AUTOSAR XML (schema 4-2-2)
package /ComponentTypes
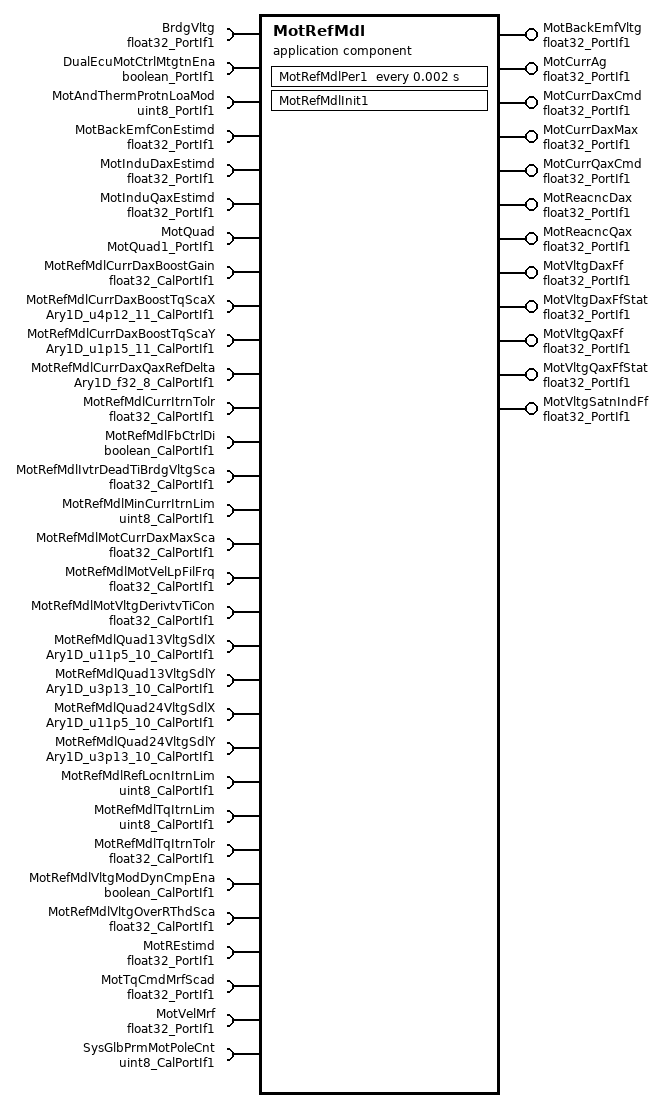
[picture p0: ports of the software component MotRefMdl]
  application sw component type MotRefMdl
    12 x provide port, all with nonqueued-sender-com-spec{data-element=Val, init-value=0}, provided-interface=float32_PortIf1:
      MotBackEmfVltg
      MotCurrAg
      MotCurrDaxCmd
      MotCurrDaxMax
      MotCurrQaxCmd
      MotReacncDax
      MotReacncQax
      MotVltgDaxFf
      MotVltgDaxFfStat
      MotVltgQaxFf
      MotVltgQaxFfStat
      MotVltgSatnIndFf
    31 x require port:
      BrdgVltg: nonqueued-receiver-com-spec{data-element=Val, filter=data-filter-type=ALWAYS, init-value=6}, required-interface=float32_PortIf1
      DualEcuMotCtrlMtgtnEna: nonqueued-receiver-com-spec{data-element=Logl, filter=data-filter-type=ALWAYS, init-value=0}, required-interface=boolean_PortIf1
      MotAndThermProtnLoaMod: nonqueued-receiver-com-spec{data-element=Val, filter=data-filter-type=ALWAYS, init-value=0}, required-interface=uint8_PortIf1
      MotBackEmfConEstimd: nonqueued-receiver-com-spec{data-element=Val, filter=data-filter-type=ALWAYS, init-value=0.025}, required-interface=float32_PortIf1
      MotInduDaxEstimd: nonqueued-receiver-com-spec{data-element=Val, filter=data-filter-type=ALWAYS, init-value=0.00011889}, required-interface=float32_PortIf1
      MotInduQaxEstimd: nonqueued-receiver-com-spec{data-element=Val, filter=data-filter-type=ALWAYS, init-value=0.00011889}, required-interface=float32_PortIf1
      MotQuad: nonqueued-receiver-com-spec{data-element=Val, filter=data-filter-type=ALWAYS, init-value=1}, required-interface=MotQuad1_PortIf1
      MotRefMdlCurrDaxBoostGain: parameter-require-com-spec{init-value=0, parameter=Val}, required-interface=float32_CalPortIf1
      MotRefMdlCurrDaxBoostTqScaX: parameter-require-com-spec{init-value=[0, 6144, 7168, 8192, 9216, 10240, 12288, 14336, 16384, 18432, 20480], parameter=Ary1D}, required-interface=Ary1D_u4p12_11_CalPortIf1
      MotRefMdlCurrDaxBoostTqScaY: parameter-require-com-spec{init-value=[0, 16384, 19661, 22938, 23757, 25395, 27034, 27853, 29491, 31130, 32768], parameter=Ary1D}, required-interface=Ary1D_u1p15_11_CalPortIf1
      MotRefMdlCurrDaxQaxRefDelta: parameter-require-com-spec{init-value=[-3.1415927, -2.3561945, -1.5707964, -0.7853982, 0, 0.7853982, 1.5707964, 2.3561945], parameter=Ary1D}, required-interface=Ary1D_f32_8_CalPortIf1
      MotRefMdlCurrItrnTolr: parameter-require-com-spec{init-value=0.1, parameter=Val}, required-interface=float32_CalPortIf1
      MotRefMdlFbCtrlDi: parameter-require-com-spec{init-value=0, parameter=Logl}, required-interface=boolean_CalPortIf1
      MotRefMdlIvtrDeadTiBrdgVltgSca: parameter-require-com-spec{init-value=1, parameter=Val}, required-interface=float32_CalPortIf1
      MotRefMdlMinCurrItrnLim: parameter-require-com-spec{init-value=3, parameter=Val}, required-interface=uint8_CalPortIf1
      MotRefMdlMotCurrDaxMaxSca: parameter-require-com-spec{init-value=1, parameter=Val}, required-interface=float32_CalPortIf1
      MotRefMdlMotVelLpFilFrq: parameter-require-com-spec{init-value=125, parameter=Val}, required-interface=float32_CalPortIf1
      MotRefMdlMotVltgDerivtvTiCon: parameter-require-com-spec{init-value=0.0026526, parameter=Val}, required-interface=float32_CalPortIf1
      MotRefMdlQuad13VltgSdlX: parameter-require-com-spec{init-value=[0, 3200, 6400, 9600, 16000, 19200, 22400, 25600, 28800, 35200], parameter=Ary1D}, required-interface=Ary1D_u11p5_10_CalPortIf1
      MotRefMdlQuad13VltgSdlY: parameter-require-com-spec{init-value=10 x 0, parameter=Ary1D}, required-interface=Ary1D_u3p13_10_CalPortIf1
      MotRefMdlQuad24VltgSdlX: parameter-require-com-spec{init-value=[0, 3200, 6400, 9600, 16000, 19200, 22400, 25600, 28800, 35200], parameter=Ary1D}, required-interface=Ary1D_u11p5_10_CalPortIf1
      MotRefMdlQuad24VltgSdlY: parameter-require-com-spec{init-value=10 x 0, parameter=Ary1D}, required-interface=Ary1D_u3p13_10_CalPortIf1
      MotRefMdlRefLocnItrnLim: parameter-require-com-spec{init-value=10, parameter=Val}, required-interface=uint8_CalPortIf1
      MotRefMdlTqItrnLim: parameter-require-com-spec{init-value=3, parameter=Val}, required-interface=uint8_CalPortIf1
      MotRefMdlTqItrnTolr: parameter-require-com-spec{init-value=0.015, parameter=Val}, required-interface=float32_CalPortIf1
      MotRefMdlVltgModDynCmpEna: parameter-require-com-spec{init-value=0, parameter=Logl}, required-interface=boolean_CalPortIf1
      MotRefMdlVltgOverRThdSca: parameter-require-com-spec{init-value=0.25, parameter=Val}, required-interface=float32_CalPortIf1
      MotREstimd: nonqueued-receiver-com-spec{data-element=Val, filter=data-filter-type=ALWAYS, init-value=0.0139083}, required-interface=float32_PortIf1
      MotTqCmdMrfScad: nonqueued-receiver-com-spec{data-element=Val, filter=data-filter-type=ALWAYS, init-value=0}, required-interface=float32_PortIf1
      MotVelMrf: nonqueued-receiver-com-spec{data-element=Val, filter=data-filter-type=ALWAYS, init-value=0}, required-interface=float32_PortIf1
      SysGlbPrmMotPoleCnt: parameter-require-com-spec{init-value=8, parameter=Val}, required-interface=uint8_CalPortIf1
    behavior MotRefMdl_InternalBehavior: data-type-mapping=Nexteer
      ar-typed-per-instance-memorys:
        28 x data, all with sw-calibration-access=READ-ONLY:
          CosDelta: type=Ary1D_f32_8
          dMotRefMdlCurrDaxAtPeakTq: type=float32
          dMotRefMdlCurrDaxMin: type=float32
          dMotRefMdlCurrQaxMin: type=float32
          dMotRefMdlCurrSqdMin: type=float32
          dMotRefMdlInterCalcnCurrDaxMax: type=float32
          dMotRefMdlMinCurrNrItrn: type=uint8
          dMotRefMdlMotCurrDaxBoost: type=float32
          dMotRefMdlMotTqCmdLimd: type=float32
          dMotRefMdlMotVelFildFf: type=float32
          dMotRefMdlMotVltgDaxFfDyn: type=float32
          dMotRefMdlMotVltgDaxFfDynTerm: type=float32
          dMotRefMdlMotVltgDaxFfStat: type=float32
          dMotRefMdlMotVltgQaxFfDyn: type=float32
          dMotRefMdlMotVltgQaxFfDynTerm: type=float32
          dMotRefMdlMotVltgQaxFfStat: type=float32
          dMotRefMdlPeakTq: type=float32
          dMotRefMdlPeakTqNrItrn: type=uint8
          dMotRefMdlPhaAdvAtPeakTq: type=float32
          dMotRefMdlReacncDaxOverR: type=float32
          dMotRefMdlReacncQaxOverR: type=float32
          dMotRefMdlRelncTqCoeff: type=float32
          MotCurrDaxCmdPrev: type=float32
          MotCurrQaxCmdPrev: type=float32
          MotVelLpFil: type=FilLpRec1
          SinDelta: type=Ary1D_f32_8
          VltgDaxFfTermPrev: type=float32
          VltgQaxFfTermPrev: type=float32
      init event MotRefMdlInit1_InitEvent: start-on-event=MotRefMdlInit1
      timing event TMT_MotRefMdlPer1: start-on-event=MotRefMdlPer1, period=0.002
      port-api-options:
        enable-take-address=false, error-handling=NO-TRANSFORMER-ERROR-HANDLING, indirect-api=false, port=BrdgVltg
        enable-take-address=false, error-handling=NO-TRANSFORMER-ERROR-HANDLING, indirect-api=false, port=DualEcuMotCtrlMtgtnEna
        enable-take-address=false, error-handling=NO-TRANSFORMER-ERROR-HANDLING, indirect-api=false, port=MotAndThermProtnLoaMod
        enable-take-address=false, error-handling=NO-TRANSFORMER-ERROR-HANDLING, indirect-api=false, port=MotBackEmfConEstimd
        enable-take-address=false, error-handling=NO-TRANSFORMER-ERROR-HANDLING, indirect-api=false, port=MotBackEmfVltg
        enable-take-address=false, error-handling=NO-TRANSFORMER-ERROR-HANDLING, indirect-api=false, port=MotCurrAg
        enable-take-address=false, error-handling=NO-TRANSFORMER-ERROR-HANDLING, indirect-api=false, port=MotCurrDaxCmd
        enable-take-address=false, error-handling=NO-TRANSFORMER-ERROR-HANDLING, indirect-api=false, port=MotCurrDaxMax
        enable-take-address=false, error-handling=NO-TRANSFORMER-ERROR-HANDLING, indirect-api=false, port=MotCurrQaxCmd
        enable-take-address=false, error-handling=NO-TRANSFORMER-ERROR-HANDLING, indirect-api=false, port=MotInduDaxEstimd
        enable-take-address=false, error-handling=NO-TRANSFORMER-ERROR-HANDLING, indirect-api=false, port=MotInduQaxEstimd
        enable-take-address=false, error-handling=NO-TRANSFORMER-ERROR-HANDLING, indirect-api=false, port=MotQuad
        enable-take-address=false, error-handling=NO-TRANSFORMER-ERROR-HANDLING, indirect-api=false, port=MotReacncDax
        enable-take-address=false, error-handling=NO-TRANSFORMER-ERROR-HANDLING, indirect-api=false, port=MotReacncQax
        enable-take-address=false, error-handling=NO-TRANSFORMER-ERROR-HANDLING, indirect-api=false, port=MotRefMdlCurrDaxBoostGain
        enable-take-address=false, error-handling=NO-TRANSFORMER-ERROR-HANDLING, indirect-api=false, port=MotRefMdlCurrDaxBoostTqScaX
        enable-take-address=false, error-handling=NO-TRANSFORMER-ERROR-HANDLING, indirect-api=false, port=MotRefMdlCurrDaxBoostTqScaY
        enable-take-address=false, error-handling=NO-TRANSFORMER-ERROR-HANDLING, indirect-api=false, port=MotRefMdlCurrDaxQaxRefDelta
        enable-take-address=false, error-handling=NO-TRANSFORMER-ERROR-HANDLING, indirect-api=false, port=MotRefMdlCurrItrnTolr
        enable-take-address=false, error-handling=NO-TRANSFORMER-ERROR-HANDLING, indirect-api=false, port=MotRefMdlFbCtrlDi
        enable-take-address=false, error-handling=NO-TRANSFORMER-ERROR-HANDLING, indirect-api=false, port=MotRefMdlIvtrDeadTiBrdgVltgSca
        enable-take-address=false, error-handling=NO-TRANSFORMER-ERROR-HANDLING, indirect-api=false, port=MotRefMdlMinCurrItrnLim
        enable-take-address=false, error-handling=NO-TRANSFORMER-ERROR-HANDLING, indirect-api=false, port=MotRefMdlMotCurrDaxMaxSca
        enable-take-address=false, error-handling=NO-TRANSFORMER-ERROR-HANDLING, indirect-api=false, port=MotRefMdlMotVelLpFilFrq
        enable-take-address=false, error-handling=NO-TRANSFORMER-ERROR-HANDLING, indirect-api=false, port=MotRefMdlMotVltgDerivtvTiCon
        enable-take-address=false, error-handling=NO-TRANSFORMER-ERROR-HANDLING, indirect-api=false, port=MotRefMdlQuad13VltgSdlX
        enable-take-address=false, error-handling=NO-TRANSFORMER-ERROR-HANDLING, indirect-api=false, port=MotRefMdlQuad13VltgSdlY
        enable-take-address=false, error-handling=NO-TRANSFORMER-ERROR-HANDLING, indirect-api=false, port=MotRefMdlQuad24VltgSdlX
        enable-take-address=false, error-handling=NO-TRANSFORMER-ERROR-HANDLING, indirect-api=false, port=MotRefMdlQuad24VltgSdlY
        enable-take-address=false, error-handling=NO-TRANSFORMER-ERROR-HANDLING, indirect-api=false, port=MotRefMdlRefLocnItrnLim
        enable-take-address=false, error-handling=NO-TRANSFORMER-ERROR-HANDLING, indirect-api=false, port=MotRefMdlTqItrnLim
        enable-take-address=false, error-handling=NO-TRANSFORMER-ERROR-HANDLING, indirect-api=false, port=MotRefMdlTqItrnTolr
        enable-take-address=false, error-handling=NO-TRANSFORMER-ERROR-HANDLING, indirect-api=false, port=MotRefMdlVltgModDynCmpEna
        enable-take-address=false, error-handling=NO-TRANSFORMER-ERROR-HANDLING, indirect-api=false, port=MotRefMdlVltgOverRThdSca
        enable-take-address=false, error-handling=NO-TRANSFORMER-ERROR-HANDLING, indirect-api=false, port=MotREstimd
        enable-take-address=false, error-handling=NO-TRANSFORMER-ERROR-HANDLING, indirect-api=false, port=MotTqCmdMrfScad
        enable-take-address=false, error-handling=NO-TRANSFORMER-ERROR-HANDLING, indirect-api=false, port=MotVelMrf
        enable-take-address=false, error-handling=NO-TRANSFORMER-ERROR-HANDLING, indirect-api=false, port=MotVltgDaxFf
        enable-take-address=false, error-handling=NO-TRANSFORMER-ERROR-HANDLING, indirect-api=false, port=MotVltgDaxFfStat
        enable-take-address=false, error-handling=NO-TRANSFORMER-ERROR-HANDLING, indirect-api=false, port=MotVltgQaxFf
        enable-take-address=false, error-handling=NO-TRANSFORMER-ERROR-HANDLING, indirect-api=false, port=MotVltgQaxFfStat
        enable-take-address=false, error-handling=NO-TRANSFORMER-ERROR-HANDLING, indirect-api=false, port=MotVltgSatnIndFf
        enable-take-address=false, error-handling=NO-TRANSFORMER-ERROR-HANDLING, indirect-api=false, port=SysGlbPrmMotPoleCnt
      runnable MotRefMdlInit1
      runnable MotRefMdlPer1
        data-receive-point-by-arguments:
          10 x access:
            REC_BrdgVltg_Val: accessed-variable=BrdgVltg.Val
            REC_DualEcuMotCtrlMtgtnEna_Logl: accessed-variable=DualEcuMotCtrlMtgtnEna.Logl
            REC_MotAndThermProtnLoaMod_Val: accessed-variable=MotAndThermProtnLoaMod.Val
            REC_MotBackEmfConEstimd_Val: accessed-variable=MotBackEmfConEstimd.Val
            REC_MotInduDaxEstimd_Val: accessed-variable=MotInduDaxEstimd.Val
            REC_MotInduQaxEstimd_Val: accessed-variable=MotInduQaxEstimd.Val
            REC_MotQuad_Val: accessed-variable=MotQuad.Val
            REC_MotREstimd_Val: accessed-variable=MotREstimd.Val
            REC_MotTqCmdMrfScad_Val: accessed-variable=MotTqCmdMrfScad.Val
            REC_MotVelMrf_Val: accessed-variable=MotVelMrf.Val
        data-send-points:
          12 x access:
            SEND_MotCtrlMotBackEmfVltg_Val: accessed-variable=MotBackEmfVltg.Val
            SEND_MotCurrAg_Val: accessed-variable=MotCurrAg.Val
            SEND_MotCurrDaxCmd_Val: accessed-variable=MotCurrDaxCmd.Val
            SEND_MotCurrDaxMax_Val: accessed-variable=MotCurrDaxMax.Val
            SEND_MotCurrQaxCmd_Val: accessed-variable=MotCurrQaxCmd.Val
            SEND_MotReacncDax_Val_1: accessed-variable=MotReacncDax.Val
            SEND_MotReacncQax_Val_1: accessed-variable=MotReacncQax.Val
            SEND_MotVltgDaxFf_Val: accessed-variable=MotVltgDaxFf.Val
            SEND_MotVltgDaxFfStat_Val: accessed-variable=MotVltgDaxFfStat.Val
            SEND_MotVltgQaxFf_Val: accessed-variable=MotVltgQaxFf.Val
            SEND_MotVltgQaxFfStat_Val: accessed-variable=MotVltgQaxFfStat.Val
            SEND_MotVltgSatnIndFf_Val: accessed-variable=MotVltgSatnIndFf.Val
  swc implementation MotRefMdl_Implementation: behavior=MotRefMdl_InternalBehavior
    code-descriptors:
      code Default: artifact-descriptors=autosar-engineering-object={short-label=Default, category=SWSRC}
